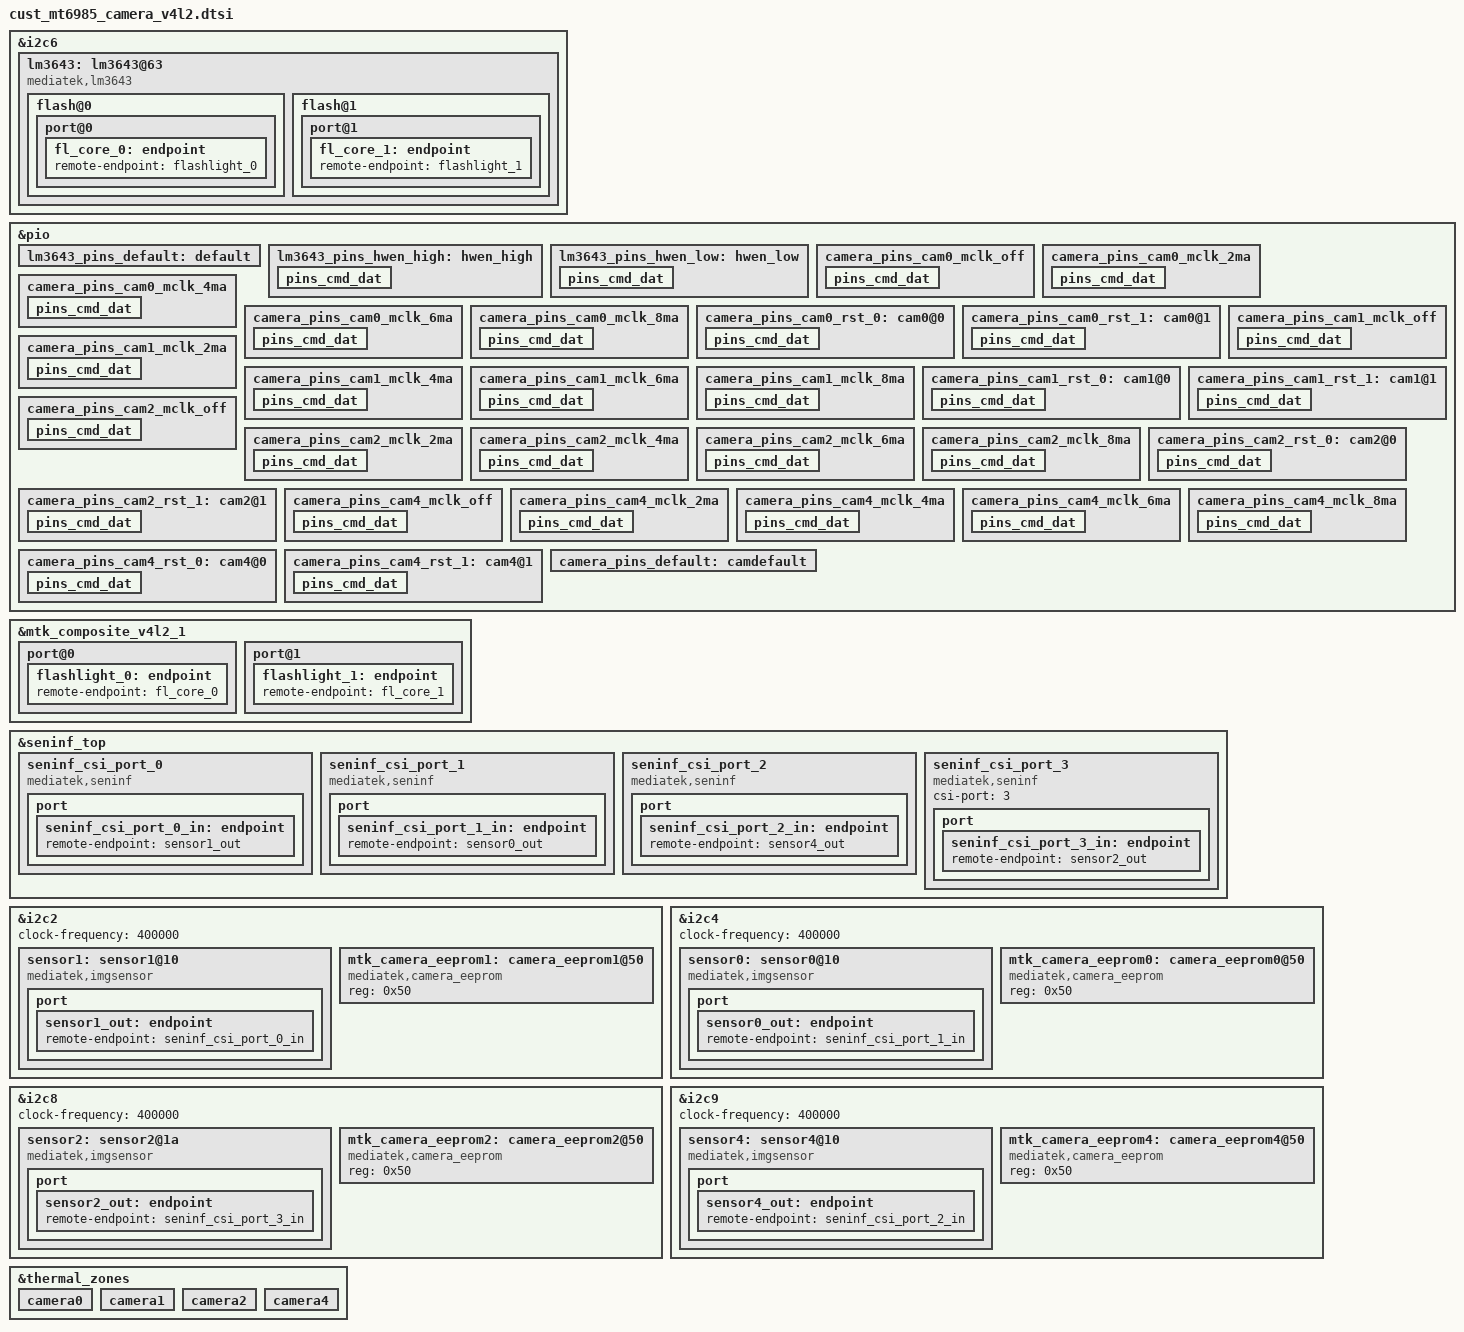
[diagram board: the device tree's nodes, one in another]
// SPDX-License-Identifier: GPL-2.0
/* Copyright (c) 2020 MediaTek Inc. */

#include <dt-bindings/clock/mt6985-clk.h>

&i2c6 {
	lm3643:lm3643@63 {
		compatible = "mediatek,lm3643";
		reg = <0x63>;
		#cooling-cells = <2>;
		pinctrl-names = "default", "hwen_high", "hwen_low";
		pinctrl-0 = <&lm3643_pins_default>;
		pinctrl-1 = <&lm3643_pins_hwen_high>;
		pinctrl-2 = <&lm3643_pins_hwen_low>;
		status = "okay";
		flash@0{
			reg = <0>;
			type = <0>;
			ct = <0>;
			part = <0>;
			port@0 {
				fl_core_0: endpoint {
					remote-endpoint = <&flashlight_0>;
				};
			};
		};
		flash@1{
			reg = <1>;
			type = <0>;
			ct = <1>;
			part = <0>;
			port@1 {
				fl_core_1: endpoint {
					remote-endpoint = <&flashlight_1>;
				};
			};
		};
	};
};

&pio {
	lm3643_pins_default: default {
	};

	lm3643_pins_hwen_high: hwen_high {
		pins_cmd_dat {
			pinmux = <PINMUX_GPIO31__FUNC_GPIO31>;
			slew-rate = <1>;
			output-high;
		};
	};

	lm3643_pins_hwen_low: hwen_low {
		pins_cmd_dat {
			pinmux = <PINMUX_GPIO31__FUNC_GPIO31>;
			slew-rate = <1>;
			output-low;
		};
	};
};

&mtk_composite_v4l2_1 {
	port@0 {
		flashlight_0: endpoint {
			remote-endpoint = <&fl_core_0>;
		};
	};
	port@1 {
		flashlight_1: endpoint {
			remote-endpoint = <&fl_core_1>;
		};
	};
};

&seninf_top {
		seninf_csi_port_0: seninf_csi_port_0 {
			compatible = "mediatek,seninf";
			csi-port = "0";
			dphy_settle_delay_dt = <17>;
#if 0
			nvmem-cells = <&csi_efuse0>;
			nvmem-cell-names = "rg_csi";
#endif
			port {
				seninf_csi_port_0_in: endpoint {
					remote-endpoint = <&sensor1_out>;
				};
			};
		};

		seninf_csi_port_1: seninf_csi_port_1 {
			compatible = "mediatek,seninf";
			csi-port = "1";
			hs_trail_parameter = <0x20>;
#if 0
			nvmem-cells = <&csi_efuse1>;
			nvmem-cell-names = "rg_csi";
#endif
			port {
				seninf_csi_port_1_in: endpoint {
					remote-endpoint = <&sensor0_out>;
				};
			};
		};

		seninf_csi_port_2: seninf_csi_port_2 {
			compatible = "mediatek,seninf";
			csi-port = "2";
			hs_trail_parameter = <0x20>;
#if 0
			nvmem-cells = <&csi_efuse2>;
			nvmem-cell-names = "rg_csi";
#endif
			port {
				seninf_csi_port_2_in: endpoint {
					remote-endpoint = <&sensor4_out>;
				};
			};
		};
		seninf_csi_port_3: seninf_csi_port_3 {
			compatible = "mediatek,seninf";
			csi-port = "3";
#if 0
			nvmem-cells = <&csi_efuse2>;
			nvmem-cell-names = "rg_csi";
#endif
			port {
				seninf_csi_port_3_in: endpoint {
					remote-endpoint = <&sensor2_out>;
				};
			};
		};
};

/* CAMERA GPIO standardization */
&pio {
	camera_pins_cam0_mclk_off: camera_pins_cam0_mclk_off {
		pins_cmd_dat {
			pinmux = <PINMUX_GPIO208__FUNC_GPIO208>;
			drive-strength = <1>;
		};
	};
	camera_pins_cam0_mclk_2ma: camera_pins_cam0_mclk_2ma {
		pins_cmd_dat {
			pinmux = <PINMUX_GPIO208__FUNC_CMMCLK3>;
			drive-strength = <0>;
		};
	};
	camera_pins_cam0_mclk_4ma: camera_pins_cam0_mclk_4ma {
		pins_cmd_dat {
			pinmux = <PINMUX_GPIO208__FUNC_CMMCLK3>;
			drive-strength = <1>;
		};
	};
	camera_pins_cam0_mclk_6ma: camera_pins_cam0_mclk_6ma {
		pins_cmd_dat {
			pinmux = <PINMUX_GPIO208__FUNC_CMMCLK3>;
			drive-strength = <2>;
		};
	};
	camera_pins_cam0_mclk_8ma: camera_pins_cam0_mclk_8ma {
		pins_cmd_dat {
			pinmux = <PINMUX_GPIO208__FUNC_CMMCLK3>;
			drive-strength = <3>;
		};
	};
	camera_pins_cam0_rst_0: cam0@0 {
		pins_cmd_dat {
			pinmux = <PINMUX_GPIO202__FUNC_GPIO202>;
			slew-rate = <1>;
			output-low;
		};
	};
	camera_pins_cam0_rst_1: cam0@1 {
		pins_cmd_dat {
			pinmux = <PINMUX_GPIO202__FUNC_GPIO202>;
			slew-rate = <1>;
			output-high;
		};
	};
	camera_pins_cam1_mclk_off: camera_pins_cam1_mclk_off {
		pins_cmd_dat {
			pinmux = <PINMUX_GPIO209__FUNC_GPIO209>;
			drive-strength = <1>;
		};
	};
	camera_pins_cam1_mclk_2ma: camera_pins_cam1_mclk_2ma {
		pins_cmd_dat {
			pinmux = <PINMUX_GPIO209__FUNC_CMMCLK4>;
			drive-strength = <0>;
		};
	};
	camera_pins_cam1_mclk_4ma: camera_pins_cam1_mclk_4ma {
		pins_cmd_dat {
			pinmux = <PINMUX_GPIO209__FUNC_CMMCLK4>;
			drive-strength = <1>;
		};
	};
	camera_pins_cam1_mclk_6ma: camera_pins_cam1_mclk_6ma {
		pins_cmd_dat {
			pinmux = <PINMUX_GPIO209__FUNC_CMMCLK4>;
			drive-strength = <2>;
		};
	};
	camera_pins_cam1_mclk_8ma: camera_pins_cam1_mclk_8ma {
		pins_cmd_dat {
			pinmux = <PINMUX_GPIO209__FUNC_CMMCLK4>;
			drive-strength = <3>;
		};
	};
	camera_pins_cam1_rst_0: cam1@0 {
		pins_cmd_dat {
			pinmux = <PINMUX_GPIO199__FUNC_GPIO199>;
			slew-rate = <1>;
			output-low;
		};
	};
	camera_pins_cam1_rst_1: cam1@1 {
		pins_cmd_dat {
			pinmux = <PINMUX_GPIO199__FUNC_GPIO199>;
			slew-rate = <1>;
			output-high;
		};
	};
	camera_pins_cam2_mclk_off: camera_pins_cam2_mclk_off {
		pins_cmd_dat {
			pinmux = <PINMUX_GPIO198__FUNC_GPIO198>;
			drive-strength = <1>;
		};
	};
	camera_pins_cam2_mclk_2ma: camera_pins_cam2_mclk_2ma {
		pins_cmd_dat {
			pinmux = <PINMUX_GPIO198__FUNC_CMMCLK2>;
			drive-strength = <0>;
		};
	};
	camera_pins_cam2_mclk_4ma: camera_pins_cam2_mclk_4ma {
		pins_cmd_dat {
			pinmux = <PINMUX_GPIO198__FUNC_CMMCLK2>;
			drive-strength = <1>;
		};
	};
	camera_pins_cam2_mclk_6ma: camera_pins_cam2_mclk_6ma {
		pins_cmd_dat {
			pinmux = <PINMUX_GPIO198__FUNC_CMMCLK2>;
			drive-strength = <2>;
		};
	};
	camera_pins_cam2_mclk_8ma: camera_pins_cam2_mclk_8ma {
		pins_cmd_dat {
			pinmux = <PINMUX_GPIO198__FUNC_CMMCLK2>;
			drive-strength = <3>;
		};
	};
	camera_pins_cam2_rst_0: cam2@0 {
		pins_cmd_dat {
			pinmux = <PINMUX_GPIO201__FUNC_GPIO201>;
			slew-rate = <1>;
			output-low;
		};
	};
	camera_pins_cam2_rst_1: cam2@1 {
		pins_cmd_dat {
			pinmux = <PINMUX_GPIO201__FUNC_GPIO201>;
			slew-rate = <1>;
			output-high;
		};
	};
	camera_pins_cam4_mclk_off: camera_pins_cam4_mclk_off {
		pins_cmd_dat {
			pinmux = <PINMUX_GPIO197__FUNC_GPIO197>;
			drive-strength = <1>;
		};
	};
	camera_pins_cam4_mclk_2ma: camera_pins_cam4_mclk_2ma {
		pins_cmd_dat {
			pinmux = <PINMUX_GPIO197__FUNC_CMMCLK1>;
			drive-strength = <0>;
		};
	};
	camera_pins_cam4_mclk_4ma: camera_pins_cam4_mclk_4ma {
		pins_cmd_dat {
			pinmux = <PINMUX_GPIO197__FUNC_CMMCLK1>;
			drive-strength = <1>;
		};
	};
	camera_pins_cam4_mclk_6ma: camera_pins_cam4_mclk_6ma {
		pins_cmd_dat {
			pinmux = <PINMUX_GPIO197__FUNC_CMMCLK1>;
			drive-strength = <2>;
		};
	};
	camera_pins_cam4_mclk_8ma: camera_pins_cam4_mclk_8ma {
		pins_cmd_dat {
			pinmux = <PINMUX_GPIO197__FUNC_CMMCLK1>;
			drive-strength = <3>;
		};
	};
	camera_pins_cam4_rst_0: cam4@0 {
		pins_cmd_dat {
			pinmux = <PINMUX_GPIO200__FUNC_GPIO200>;
			slew-rate = <1>;
			output-low;
		};
	};
	camera_pins_cam4_rst_1: cam4@1 {
		pins_cmd_dat {
			pinmux = <PINMUX_GPIO200__FUNC_GPIO200>;
			slew-rate = <1>;
			output-high;
		};
	};
	camera_pins_default: camdefault {
	};
};
/* CAMERA GPIO end */

&i2c2 {
	status = "okay";
	clock-frequency = <400000>;
	#address-cells = <1>;
	#size-cells = <0>;

	sensor1: sensor1@10 {
		compatible = "mediatek,imgsensor";
		sensor-names = "s5k3p9sp_mipi_raw";
		reg = <0x10>;
		#thermal-sensor-cells = <0>;

		pinctrl-names = "mclk_off",
				"mclk_2mA",
				"mclk_4mA",
				"mclk_6mA",
				"mclk_8mA",
				"rst_low",
				"rst_high";
		pinctrl-0 = <&camera_pins_cam1_mclk_off>;
		pinctrl-1 = <&camera_pins_cam1_mclk_2ma>;
		pinctrl-2 = <&camera_pins_cam1_mclk_4ma>;
		pinctrl-3 = <&camera_pins_cam1_mclk_6ma>;
		pinctrl-4 = <&camera_pins_cam1_mclk_8ma>;
		pinctrl-5 = <&camera_pins_cam1_rst_0>;
		pinctrl-6 = <&camera_pins_cam1_rst_1>;

		avdd-supply = <&rt5133_ldo6>;
		dvdd-supply = <&rt5133_ldo7>;
		dovdd-supply = <&rt5133_ldo1>;
		afvdd-supply = <&rt5133_ldo2>;
		avdd1-supply = <&rt5133_ldo5>;

		clocks = <&topckgen_clk CLK_TOP_UNIVPLL2_192M_D32>,
			<&topckgen_clk CLK_TOP_UNIVPLL2_192M_D16>,
			<&topckgen_clk CLK_TOP_F26M_CK_D2>,
			<&topckgen_clk CLK_TOP_UNIVPLL2_192M_D10>,
			<&topckgen_clk CLK_TOP_UNIVPLL2_192M_D8>,
			<&topckgen_clk CLK_TOP_TCK_26M_MX9>,
			<&topckgen_clk CLK_TOP_UNIVPLL2_D6_D8>,
			<&topckgen_clk CLK_TOP_CAMTG5_SEL>;
		clock-names = "6", "12", "13", "19.2", "24", "26", "52", "mclk";

		status = "okay";

		port {
			sensor1_out: endpoint {
				remote-endpoint = <&seninf_csi_port_0_in>;
			};
		};
	};

	mtk_camera_eeprom1:camera_eeprom1@50 {
		compatible = "mediatek,camera_eeprom";
		reg = <0x50>;
		status = "okay";
	};
};

&i2c4 {
	status = "okay";
	clock-frequency = <400000>;
	#address-cells = <1>;
	#size-cells = <0>;

	sensor0: sensor0@10 {
		compatible = "mediatek,imgsensor";
		sensor-names = "imx766_mipi_raw",
				"imx709_mipi_raw",
				"imx866_mipi_raw";
		reg = <0x10>;
		#thermal-sensor-cells = <0>;

		pinctrl-names = "mclk_off",
				"mclk_2mA",
				"mclk_4mA",
				"mclk_6mA",
				"mclk_8mA",
				"rst_low",
				"rst_high";
		pinctrl-0 = <&camera_pins_cam0_mclk_off>;
		pinctrl-1 = <&camera_pins_cam0_mclk_2ma>;
		pinctrl-2 = <&camera_pins_cam0_mclk_4ma>;
		pinctrl-3 = <&camera_pins_cam0_mclk_6ma>;
		pinctrl-4 = <&camera_pins_cam0_mclk_8ma>;
		pinctrl-5 = <&camera_pins_cam0_rst_0>;
		pinctrl-6 = <&camera_pins_cam0_rst_1>;

		avdd-supply = <&rt5133_gpio2>;
		dvdd-supply = <&rt5133_ldo7>;
		dovdd-supply = <&rt5133_ldo1>;
		afvdd-supply = <&rt5133_gpio1>;
		avdd1-supply = <&rt5133_ldo5>;

		clocks = <&topckgen_clk CLK_TOP_UNIVPLL2_192M_D32>,
			<&topckgen_clk CLK_TOP_UNIVPLL2_192M_D16>,
			<&topckgen_clk CLK_TOP_F26M_CK_D2>,
			<&topckgen_clk CLK_TOP_UNIVPLL2_192M_D10>,
			<&topckgen_clk CLK_TOP_UNIVPLL2_192M_D8>,
			<&topckgen_clk CLK_TOP_TCK_26M_MX9>,
			<&topckgen_clk CLK_TOP_UNIVPLL2_D6_D8>,
			<&topckgen_clk CLK_TOP_CAMTG4_SEL>;
		clock-names = "6", "12", "13", "19.2", "24", "26", "52", "mclk";

		status = "okay";

		port {
			sensor0_out: endpoint {
				remote-endpoint = <&seninf_csi_port_1_in>;
			};
		};
	};

	mtk_camera_eeprom0:camera_eeprom0@50 {
		compatible = "mediatek,camera_eeprom";
		reg = <0x50>;
		status = "okay";
	};
};

&i2c8 {
	status = "okay";
	clock-frequency = <400000>;
	#address-cells = <1>;
	#size-cells = <0>;

	sensor2: sensor2@1a {
		compatible = "mediatek,imgsensor";
		sensor-names = "ov48b_mipi_raw",
				"imx519_mipi_raw",
				"imx499_mipi_raw";
		reg = <0x1a>;
		#thermal-sensor-cells = <0>;

		pinctrl-names = "mclk_off",
				"mclk_2mA",
				"mclk_4mA",
				"mclk_6mA",
				"mclk_8mA",
				"rst_low",
				"rst_high";
		pinctrl-0 = <&camera_pins_cam2_mclk_off>;
		pinctrl-1 = <&camera_pins_cam2_mclk_2ma>;
		pinctrl-2 = <&camera_pins_cam2_mclk_4ma>;
		pinctrl-3 = <&camera_pins_cam2_mclk_6ma>;
		pinctrl-4 = <&camera_pins_cam2_mclk_8ma>;
		pinctrl-5 = <&camera_pins_cam2_rst_0>;
		pinctrl-6 = <&camera_pins_cam2_rst_1>;

		avdd-supply = <&rt5133_ldo4>;
		dvdd-supply = <&rt5133_ldo8>;
		dovdd-supply = <&rt5133_ldo1>;
		afvdd-supply = <&rt5133_ldo3>;
		avdd1-supply = <&rt5133_ldo5>;

		clocks = <&topckgen_clk CLK_TOP_UNIVPLL2_192M_D32>,
			<&topckgen_clk CLK_TOP_UNIVPLL2_192M_D16>,
			<&topckgen_clk CLK_TOP_F26M_CK_D2>,
			<&topckgen_clk CLK_TOP_UNIVPLL2_192M_D10>,
			<&topckgen_clk CLK_TOP_UNIVPLL2_192M_D8>,
			<&topckgen_clk CLK_TOP_TCK_26M_MX9>,
			<&topckgen_clk CLK_TOP_UNIVPLL2_D6_D8>,
			<&topckgen_clk CLK_TOP_CAMTG3_SEL>;
		clock-names = "6", "12", "13", "19.2", "24", "26", "52", "mclk";

		status = "okay";

		port {
			sensor2_out: endpoint {
				remote-endpoint = <&seninf_csi_port_3_in>;
			};
		};
	};

	mtk_camera_eeprom2:camera_eeprom2@50 {
		compatible = "mediatek,camera_eeprom";
		reg = <0x50>;
		status = "okay";
	};
};

&i2c9 {
	status = "okay";
	clock-frequency = <400000>;
	#address-cells = <1>;
	#size-cells = <0>;

	sensor4: sensor4@10 {
		compatible = "mediatek,imgsensor";
		sensor-names = "s5k3m5sx_mipi_raw";
		reg = <0x10>;
		#thermal-sensor-cells = <0>;
		pinctrl-names = "mclk_off",
				"mclk_2mA",
				"mclk_4mA",
				"mclk_6mA",
				"mclk_8mA",
				"rst_low",
				"rst_high";
		pinctrl-0 = <&camera_pins_cam4_mclk_off>;
		pinctrl-1 = <&camera_pins_cam4_mclk_2ma>;
		pinctrl-2 = <&camera_pins_cam4_mclk_4ma>;
		pinctrl-3 = <&camera_pins_cam4_mclk_6ma>;
		pinctrl-4 = <&camera_pins_cam4_mclk_8ma>;
		pinctrl-5 = <&camera_pins_cam4_rst_0>;
		pinctrl-6 = <&camera_pins_cam4_rst_1>;

		avdd-supply = <&rt5133_ldo6>;
		dvdd-supply = <&rt5133_gpio3>;
		dovdd-supply = <&rt5133_ldo1>;
		afvdd-supply = <&rt5133_ldo2>;
		avdd1-supply = <&rt5133_ldo5>;

		clocks = <&topckgen_clk CLK_TOP_UNIVPLL2_192M_D32>,
			<&topckgen_clk CLK_TOP_UNIVPLL2_192M_D16>,
			<&topckgen_clk CLK_TOP_F26M_CK_D2>,
			<&topckgen_clk CLK_TOP_UNIVPLL2_192M_D10>,
			<&topckgen_clk CLK_TOP_UNIVPLL2_192M_D8>,
			<&topckgen_clk CLK_TOP_TCK_26M_MX9>,
			<&topckgen_clk CLK_TOP_UNIVPLL2_D6_D8>,
			<&topckgen_clk CLK_TOP_CAMTG2_SEL>;
		clock-names = "6", "12", "13", "19.2", "24", "26", "52", "mclk";

		status = "okay";

		port {
			sensor4_out: endpoint {
				remote-endpoint = <&seninf_csi_port_2_in>;
			};
		};
	};

	mtk_camera_eeprom4:camera_eeprom4@50 {
		compatible = "mediatek,camera_eeprom";
		reg = <0x50>;
		status = "okay";
	};
};

&thermal_zones {
	camera0: camera0 {
		polling-delay = <0>; /* milliseconds */
		polling-delay-passive = <0>; /* milliseconds */
		thermal-sensors = <&sensor0>;
	};
	camera1: camera1 {
		polling-delay = <0>; /* milliseconds */
		polling-delay-passive = <0>; /* milliseconds */
		thermal-sensors = <&sensor1>;
	};
	camera2: camera2 {
		polling-delay = <0>; /* milliseconds */
		polling-delay-passive = <0>; /* milliseconds */
		thermal-sensors = <&sensor2>;
	};
	camera4: camera4 {
		polling-delay = <0>; /* milliseconds */
		polling-delay-passive = <0>; /* milliseconds */
		thermal-sensors = <&sensor4>;
	};
};

